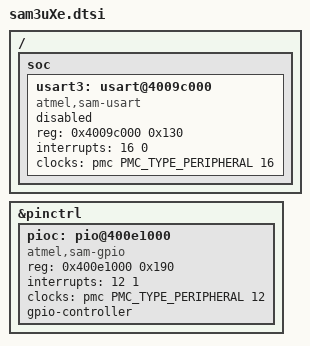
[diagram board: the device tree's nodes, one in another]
/*
 * Copyright (c) 2023 Chen Xingyu <hi@xingrz.me>
 *
 * SPDX-License-Identifier: Apache-2.0
 */

/ {
	soc {
		usart3: usart@4009c000 {
			compatible = "atmel,sam-usart";
			reg = <0x4009c000 0x130>;
			interrupts = <16 0>;
			clocks = <&pmc PMC_TYPE_PERIPHERAL 16>;
			status = "disabled";
		};
	};
};

&pinctrl {
	pioc: pio@400e1000 {
		compatible = "atmel,sam-gpio";
		reg = <0x400e1000 0x190>;
		interrupts = <12 1>;
		clocks = <&pmc PMC_TYPE_PERIPHERAL 12>;
		gpio-controller;
		#gpio-cells = <2>;
		#atmel,pin-cells = <2>;
	};
};
